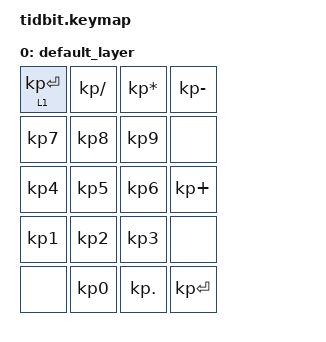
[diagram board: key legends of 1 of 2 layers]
/*
 * Copyright (c) 2020 The ZMK Contributors
 *
 * SPDX-License-Identifier: MIT
 */

#include <behaviors.dtsi>
#include <dt-bindings/zmk/bt.h>
#include <dt-bindings/zmk/keys.h>
#include <dt-bindings/zmk/outputs.h>

    &kscan0{
    diode-direction = "col2row";
    };

    // &default_transform {
    // /delete-property/ map;
    // map = <
    //     // 新映射：将第一行第一个键与第二个键交换位置
    //     RC(0,0) RC(0,1) RC(0,2) RC(0,3)
    //     RC(1,0) RC(1,1) RC(1,2) 
    //     RC(2,0) RC(2,1) RC(2,2) RC(2,3)
    //     RC(3,0) RC(3,1) RC(3,2) 
    //             RC(4,1) RC(4,2) RC(4,3)
    // >;
    // };

/* Enable ONLY ONE of the &encoder_1 nodes. They are wired to the same pins.*/
/*
&encoder_1 {
    status = "disable";
};
&encoder_1_top_left {
    status = "disable";
};
*/

/*
&encoder_2 {
    status = "disable";
};

&encoder_3 {
    status = "disable";
};
*/

&encoder_4 {
    status = "disable";
};

/* Add any encoder(s) you have enabled to the sensors node, separated by spaces. */
&sensors {
    sensors = <&encoder_4>;
//    status = "disable";
};

/ {
    keymap {
        compatible = "zmk,keymap";

        default_layer {
            bindings = <
                &lt 1 KP_ENTER  &kp KP_SLASH    &kp KP_ASTERISK &kp KP_MINUS
                &kp KP_NUMBER_7 &kp KP_NUMBER_8 &kp KP_NUMBER_9 &none
                &kp KP_NUMBER_4 &kp KP_NUMBER_5 &kp KP_NUMBER_6 &kp KP_PLUS
                &kp KP_NUMBER_1 &kp KP_NUMBER_2 &kp KP_NUMBER_3 &none
                &none           &kp KP_NUMBER_0 &kp KP_DOT      &kp KP_ENTER
            >;

            sensor-bindings = <&inc_dec_kp C_VOLUME_UP C_VOLUME_DOWN>;
        };

         func_layer {
             bindings = <
                                &none           &sys_reset      &bootloader
                &out OUT_TOG    &out OUT_USB    &out OUT_BLE    &none
                &bt BT_SEL 0    &bt BT_PRV      &bt BT_NXT      &bt BT_CLR
                &bt BT_SEL 1    &bt BT_SEL 2    &bt BT_SEL 3    &trans
                &kp C_MUTE      &none           &none           &none
             >;

             sensor-bindings = <&inc_dec_kp C_VOLUME_UP C_VOLUME_DOWN>;
         };
    };
};
